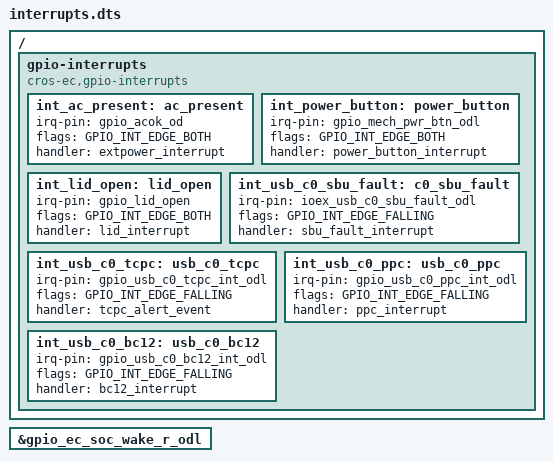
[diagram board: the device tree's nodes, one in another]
/* Copyright 2022 The ChromiumOS Authors.
 * Use of this source code is governed by a BSD-style license that can be
 * found in the LICENSE file.
 */

/ {
	gpio-interrupts {
		compatible = "cros-ec,gpio-interrupts";

		int_ac_present: ac_present {
			irq-pin = <&gpio_acok_od>;
			flags = <GPIO_INT_EDGE_BOTH>;
			handler = "extpower_interrupt";
		};
		int_power_button: power_button {
			irq-pin = <&gpio_mech_pwr_btn_odl>;
			flags = <GPIO_INT_EDGE_BOTH>;
			handler = "power_button_interrupt";
		};
		int_lid_open: lid_open {
			irq-pin = <&gpio_lid_open>;
			flags = <GPIO_INT_EDGE_BOTH>;
			handler = "lid_interrupt";
		};
		int_usb_c0_sbu_fault: c0_sbu_fault {
			irq-pin = <&ioex_usb_c0_sbu_fault_odl>;
			flags = <GPIO_INT_EDGE_FALLING>;
			handler = "sbu_fault_interrupt";
		};
		int_usb_c0_tcpc: usb_c0_tcpc {
			irq-pin = <&gpio_usb_c0_tcpc_int_odl>;
			flags = <GPIO_INT_EDGE_FALLING>;
			handler = "tcpc_alert_event";
		};
		int_usb_c0_ppc: usb_c0_ppc {
			irq-pin = <&gpio_usb_c0_ppc_int_odl>;
			flags = <GPIO_INT_EDGE_FALLING>;
			handler = "ppc_interrupt";
		};
		int_usb_c0_bc12: usb_c0_bc12 {
			irq-pin = <&gpio_usb_c0_bc12_int_odl>;
			flags = <GPIO_INT_EDGE_FALLING>;
			handler = "bc12_interrupt";
		};
	};
};

/* Required node label that doesn't is named differently on Rex */
gpio_ec_pch_wake_odl: &gpio_ec_soc_wake_r_odl {};

